# BAT32A237 register map
Vendor: CMS; Series: BAT32A237; File version: 1.2
CPU: CM0+ r0p1, little endian, MPU, no FPU, VTOR, 2 interrupt priority bits
Registers are 8-bit, read-write, reset 0x0 unless marked. A register's access mark holds for its fields unless they carry their own. Offsets are from the block's base; [hi:lo] are bit positions; lines under a group give offsets from that group; {n}, {i} and the like mark numbered series.

## IRDA — IrDA communication module based on Infrared Data Association stardard 1.0
Base 0x400440A0
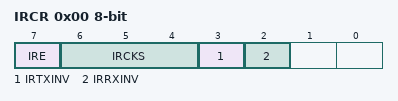
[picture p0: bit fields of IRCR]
0x00 IRCR — IrDA control register
  [7] IRE — IrRxD enable
  [6:4] IRCKS — IrRxD clock selection
  [3] IRTXINV — IrRxD data polarity switching
  [2] IRRXINV — IrRxD data polarity switching

## DMA — Enhanced DMA Controller
Base 0x40005000
{0x0+i} DMAEN{i} (i=0..4) — DMA activation enable register {i}
0x08 DMABAR 32-bit — DMA base address register
0x0C IFPRCR 32-bit — DMA Trigger Protect register
{0x10+i} DMAIF{i} (i=0..4) — DMA Trigger enable register {i}

## DMAVEC — DMA Vector and Control Data Area
Base 0x20000000
{0x0+i} VEC[{i}] (i=0..63) — DMA vector area
{0x40+0x10*i} CTRL[{i}] (i=0..39) group — DMA control data area
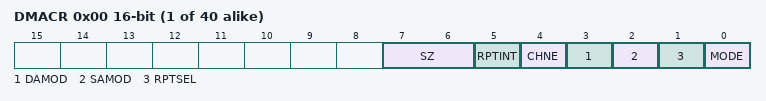
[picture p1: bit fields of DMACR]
  0x00 DMACR 16-bit — DMA Control register
    [7:6] SZ — Transfer Data size selection
      0=BYTE (8 bits); 1=HALF (16 bits); 2=WORD (32 bits)
    [5] RPTINT — Enabling/disabling repeat mode interrupts
      0=disable (Interrupt generation disabled); 1=enable (Interrupt generation enabled)
    [4] CHNE — Enabling/disabling chain transfers
      0=disable (Chain transfers disabled); 1=enable (Chain transfers enabled)
    [3] DAMOD — Destination address control
      0=Fixed; 1=Incremented
    [2] SAMOD — Source address control
      0=Fixed; 1=Incremented
    [1] RPTSEL — Repeat area selection
      0=destination (Transfer destination is the repeat area); 1=source (Transfer source is the repeat area)
    [0] MODE — Transfer mode selection
      0=Normal mode; 1=Repeat mode
  0x02 DMBLS 16-bit — DMA Block Size register
  0x04 DMACT 16-bit — DMA Transfer Count register
  0x06 DMRLD 16-bit — DMA Transfer Count Reload register
  0x08 DMSAR 32-bit — DMA Source Address register
  0x0C DMDAR 32-bit — DMA Destination Address register

## ELC — Event Link Controller
Base 0x40043400
{0x0+i} ELSELR{i:02} (reset mask 0xF) (i=0..21) — Event output destination select register {i:02}

## INT — Interrupt Controller
Base 0x40006000
{0x0+4i} IF[{i}] (i=0..31) group — Interrupt flag register
  0x00 IFL (reset mask 0x11) — Interrupt flag register
  0x01 IFH (reset mask 0x11) — Interrupt flag register
{0x100+4i} MK[{i}] (i=0..31) group — Interrupt mask register
  0x00 MKL reset 0xFFFFFFFF (reset mask 0x11) — Interrupt mask register
  0x01 MKH reset 0xFFFFFFFF (reset mask 0x11) — Interrupt mask register

## INTM — Pin input edge detection
Base 0x40045B38
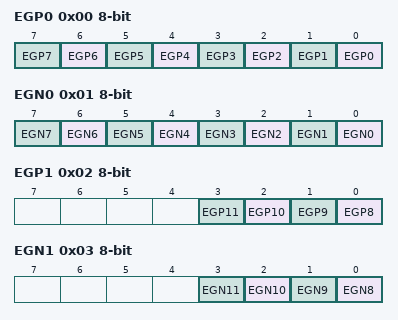
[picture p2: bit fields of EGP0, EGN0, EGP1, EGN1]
0x00 EGP0 — External interrupt rising edge enable register
  [n] EGP{n} (n=0..7)
0x01 EGN0 — External interrupt falling edge enable register
  [n] EGN{n} (n=0..7)
0x02 EGP1 — External interrupt rising edge enable register
  [n-8] EGP{n} (n=8..11)
0x03 EGN1 — External interrupt falling edge enable register
  [n-8] EGN{n} (n=8..11)

## KEY — Key interrupt
Base 0x40044B30
0x07 KRM — Key return mode register

## MISC — Miscellaneous function
Base 0x40040470
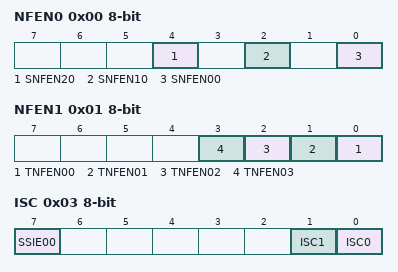
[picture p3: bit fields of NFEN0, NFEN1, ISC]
0x00 NFEN0 — Noise filter enable register 0
  [4] SNFEN20 — Enable noise filter of RxD2
  [2] SNFEN10 — Enable noise filter of RxD1
  [0] SNFEN00 — Enable noise filter of RxD0
0x01 NFEN1 — Noise filter enable register 1
  [n] TNFEN{n:02} (n=0..3) — Enable noise filter of TI{n:02}
0x03 ISC — Input switch control register
  [7] SSIE00 — The slave select input (SS00) of SPI00 is valid
    0=INVALID (The slave select input (SS00) pin is invalid); 1=VALID (The slave select input (SS00) pin is valid)
  [1] ISC1 — Switching TI03 input
    0=TI03 (Uses TI03 pin as an timer input); 1=RXD0 (Uses RXD0 pin as an timer input)
  [0] ISC0 — Switching external interrupt (INTP0) input
    0=INTP0 (Uses INTP0 pin as an external interrupt); 1=RXD0 (Uses RXD0 pin as an external interrupt)
0x04 TIOS0 (reset mask 0x83) — Timer I/O select register 0
0x05 TIOS1 (reset mask 0x1) — Timer I/O select register 1
0x0C RTCCL (reset mask 0xC3) — Real-time clock select register
